# TC37XPD register map
Vendor: Infineon; Series: ATVMC; File version: 100
CPU: other r0p0, little endian, MPU, FPU, vendor SysTick, 4 interrupt priority bits
Registers are 32-bit, read-write, reset 0x0 unless marked. A register's access mark holds for its fields unless they carry their own. Offsets are from the block's base; [hi:lo] are bit positions; lines under a group give offsets from that group; {n}, {i} and the like mark numbered series; 'fields as' and 'values as' point back to an identical list.

## CPU0 (part 1 of 2) — CPU
Base 0xF8800000
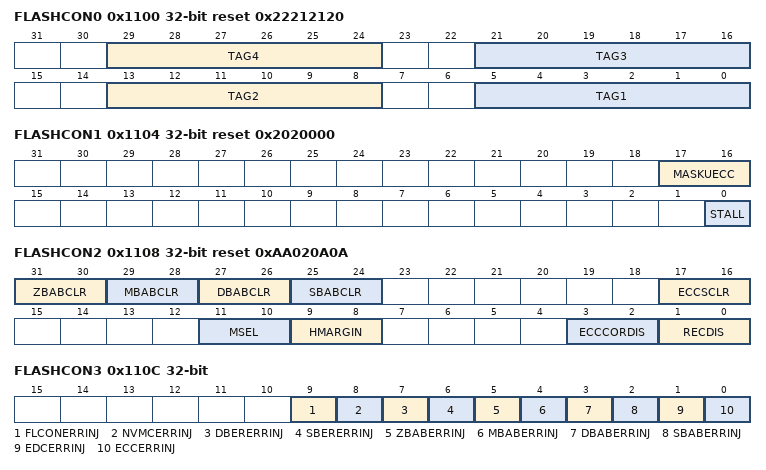
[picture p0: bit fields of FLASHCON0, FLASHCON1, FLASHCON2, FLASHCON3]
0x1100 FLASHCON0 reset 0x22212120 (reset mask 0xE2E1E1E0) — CPUx Flash Configuration Register 0 resetvalue={Application Reset:0x3F3F3F3F,CFS Value:0x22212120}
  [29:24] TAG4 — Flash Prefetch Buffer 4 Configuration. FPB is assigned to on chip bus master with master tag id equal to TAG4.
  [21:16] TAG3 — Flash Prefetch Buffer 3 Configuration. FPB is assigned to on chip bus master with master tag id equal to TAG3.
  [13:8] TAG2 — Flash Prefetch Buffer 2 Configuration. FPB is assigned to on xa0 chip xa0 bus master with master tag id equal to TAG2.
  [5:0] TAG1 — Flash Prefetch Buffer 1 Configuration. FPB is assigned to on xa0 chip xa0 bus master with master tag id equal to TAG1.
0x1104 FLASHCON1 reset 0x2020000 — CPUx Flash Configuration Register 1 resetvalue={Application Reset:0x2020000}
  [17:16] MASKUECC — Mask PFLASH Uncorrectable ECC Bit Error. No value other than 01 B or 10 B shall be programmed in the register bitfields. The system will behave as specified for 10 B if 00 B or 11 B is programmed.
  [0] STALL — Stall Bus Request. This field must not be changed while any bank is busy. The results are unpredictable. It is strongly recommended to configure this field once and avoid changing it during operation. Reading a flash bank erase counter or status register in Sleep Mode must result in a bus error independent of this field although it reports 8220 busy 8221 .
    0=Error0 (0 B Error Reading local PFlash bank erase counter or status registers when DMU STATUS.PxBUSY is set generates a bus error.); 1=1 B Stall Reading local PFlash bank erase counter or status registers when DMU HF STATUS.PxBUSY is set delays the response by inserting additional wait cycles until PxBUSY is cleared
0x1108 FLASHCON2 access per field reset 0xAA020A0A — CPUx Flash Configuration Register 2 resetvalue={Application Reset:0x0AA020A0A}
  [31:30] ZBABCLR wo — Clear ZBAB Record Registers ZBABCLR. The system will behave as specified for 10 B if 00 B or 11 B is programmed and an alarm will be generated.
  [29:28] MBABCLR wo — Clear MBAB Record Registers. The system will behave as specified for 10 B if 00 B or 11 B is programmed and an alarm will be generated.
  [27:26] DBABCLR wo — Clear DBAB Record Registers. The system will behave as specified for 10 B if 00 B or 11 B is programmed and an alarm will be generated.
  [25:24] SBABCLR wo — Clear SBAB Record Registers. The system will behave as specified for 10 B if 00 B or 11 B is programmed and an alarm will be generated.
  [17:16] ECCSCLR wo — Clear ECC Status Register. The system will behave as specified for 10 B if 00 B or 11 B is programmed and an alarm will be generated.
  [11:10] MSEL rw — Margin Read Selection. The system will behave as specified for 10 B if 00 B or 11 B is programmed and an alarm will be generated.
  [9:8] HMARGIN rw — Hard Margin Selection. This register setting is effective only if FLASHCON2.MSEL 01 B . The system will behave as specified for 10 B if 00 B or 11 B is programmed and an alarm will be generated.
  [3:2] ECCCORDIS rw — ECC Correction Disable ECCCORDIS. The system will behave as specified for 10 B if 00 B or 11 B is programmed and an alarm will be generated on the next read.
  [1:0] RECDIS rw — Address Buffer Recording Disable. The system will behave as specified for 10 B if 00 B or 11 B is programmed and an alarm will be generated. SBAB DBAB MBAB and ZBAB alarms will not be generated if RECDIS is 01 B .
0x110C FLASHCON3 — CPUx Flash Configuration Register 3 resetvalue={Application Reset:0x0}
  [9] FLCONERRINJ — Flashcon Error FLCONER Injection. Setting this bit enforces an error from the error detection logic covering FLASHCON complement pair register bits in the PFRWB RECDIS ECCCORDIS HMARGIN MSEL and all CLR bits and can be used to check the correct function of the FLCONER SMU alarm.
  [8] NVMCERRINJ — NVM Configuration NVMCER Injection. Setting this bit enforces an error from the error detection logic covering NVM configuration registers and can be used to check the correct function of the NVMCER SMU alarm.
  [7] DBERERRINJ — Double Bit Error DBER Injection. Setting this bit generates DBER SMU alarm and can be used to check the correct function of the DBER SMU alarm.
  [6] SBERERRINJ — Single Bit Error SBER Injection . Setting this bit generates SBER SMU alarm and can be used to check the correct function of this alarm.
  [5] ZBABERRINJ — Uncorrected All Zeros Bits Address Buffer ZBAB Error Injection. Error injection logic to check the correct function of the SMU alarm.
  [4] MBABERRINJ — Uncorrected Multi Bit Address Buffer MBAB Error Injection. Error injection logic to check the correct function of the SMU alarm.
  [3] DBABERRINJ — Corrected Double Bits Address Buffer DBAB Error Injection. Error injection logic to check the correct function of the SMU alarm.
  [2] SBABERRINJ — Corrected Single Bits Address Buffer SBAB Error Injection. Error injection logic to check the correct function of the SMU alarm.
  [1] EDCERRINJ — EDC Error Injection. Setting this bit enforces an error in the EDC checker logic. This can be used to check the correct function of this circuit.
  [0] ECCERRINJ — ECC Error Injection . Setting this bit enforces an error in the ECC error correction supervision circuit. This can be used to check the correct function of this circuit.
0x1110 FLASHCON4 — CPUx Flash Configuration Register 4 resetvalue={Application Reset:0x0}
  [0] DDIS — Disable direct LPB access. Disable direct access by the CPU to the Local Pflash Bank LPB .
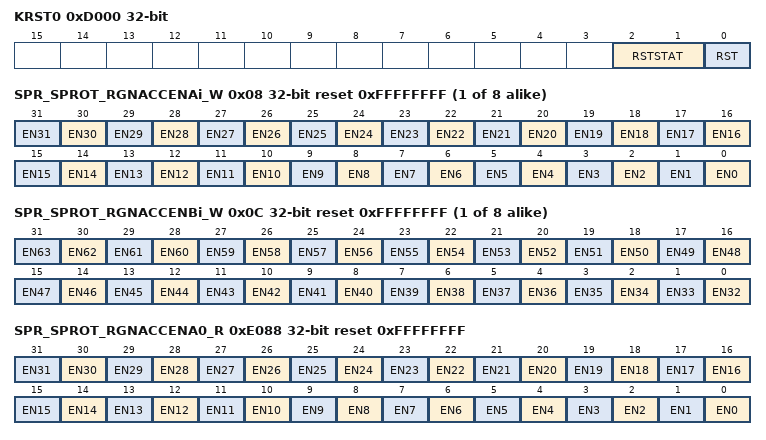
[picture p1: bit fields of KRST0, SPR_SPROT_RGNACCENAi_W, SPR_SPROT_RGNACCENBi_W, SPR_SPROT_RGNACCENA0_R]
0xD000 KRST0 access per field — CPUx Reset Register 0 resetvalue={Application Reset:0x0}
  [2:1] RSTSTAT ro — Kernel Reset Status RSTSTAT. This bit indicates wether a kernel reset was executed or not. This bit is set immediately after the execution of a kernel reset. These bits can be cleared by writing 180 1 180 to the CLR bit in the related KRSTCLR register.
  [0] RST rw — Kernel Reset RST. This reset bit can be used to request a kernel reset. The kernel reset will be executed if the reset bits of both kernel registers are set. The RST bit will be cleared re set to 180 0 180 by the BPI FPI after the kernel reset was executed.
0xD004 KRST1 — CPUx Reset Register 1 resetvalue={Application Reset:0x0}
  [0] RST — Kernel Reset RST. This reset bit can be used to request a kernel reset. The kernel reset will be executed if the reset bits of both kernel reset registers is set. The RST bit will be cleared re set to 180 0 180 after the kernel reset was executed.
0xD008 KRSTCLR wo — CPUx Reset Clear Register resetvalue={Application Reset:0x0}
  [0] CLR — Kernel Reset Status Clear CLR. Read always as 0.
{0xE000+0x10*i} RGN[{i}] (i=0..7) group
  0x00 SPR_SPROT_RGNLAi — CPUx Safety Protection SPR Region Lower Address Register 0 resetvalue={Application Reset:0x0}
    [31:5] ADDR — Region Lower Address ADDR. Bits 31 to 5 of the address which is the lower bound of the defined memory region
  0x04 SPR_SPROT_RGNUAi reset 0xFFFFFFE0 — CPUx Safety Protection SPR Region Upper Address Register 0 resetvalue={Application Reset:0x0FFFFFFE0}
    [31:5] ADDR — Region Upper Address ADDR. Bits 31 to 5 of the address which is the upper bound of the defined memory region
  0x08 SPR_SPROT_RGNACCENAi_W reset 0xFFFFFFFF — CPUx Safety Protection SPR Region Write Access Enable Register A0 resetvalue={Application Reset:0x0FFFFFFFF}
    [n] EN{n} (n=0..31) — Access Enable for Master TAG ID 31 EN31. This bit enables write access to the module kernel addresses for transactions with the Master TAG ID n
  0x0C SPR_SPROT_RGNACCENBi_W reset 0xFFFFFFFF — CPUx Safety Protection SPR Region Write Access Enable Register B0 resetvalue={Application Reset:0x0FFFFFFFF}
    [n-32] EN{n} (n=32..63) — Access Enable for Master TAG ID 63 EN63. This bit enables write access to the module kernel addresses for transactions with the Master TAG ID n
0xE088 SPR_SPROT_RGNACCENA0_R reset 0xFFFFFFFF — CPUx Safety Protection SPR Region Read Access Enable Register A7 resetvalue={Application Reset:0x0FFFFFFFF}
  [n] EN{n} (n=0..31) — Access Enable for Master TAG ID 31 EN31. This bit enables read access from the module kernel addresses for transactions with the Master TAG ID n
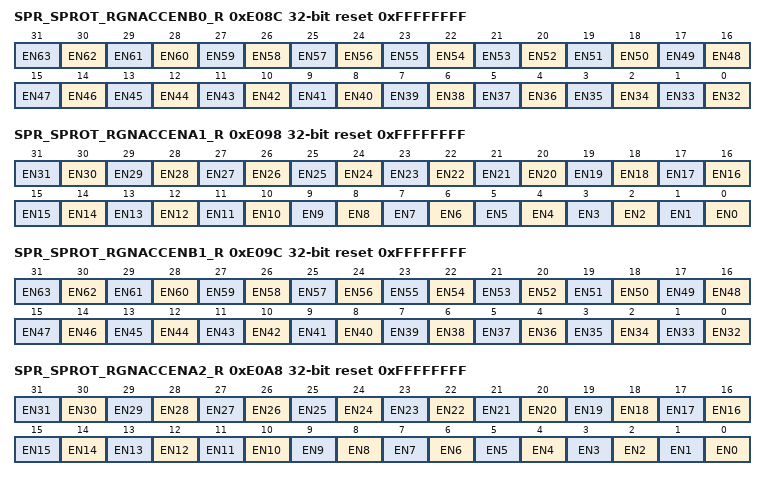
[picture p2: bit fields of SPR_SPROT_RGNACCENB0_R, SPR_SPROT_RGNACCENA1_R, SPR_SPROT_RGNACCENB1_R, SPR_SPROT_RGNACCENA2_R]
0xE08C SPR_SPROT_RGNACCENB0_R reset 0xFFFFFFFF — CPUx Safety Protection SPR Region Read Access Enable Register B7 resetvalue={Application Reset:0x0FFFFFFFF}
  [n-32] EN{n} (n=32..63) — Access Enable for Master TAG ID 63 EN63. This bit enables read access from the module kernel addresses for transactions with the Master TAG ID n
0xE098 SPR_SPROT_RGNACCENA1_R reset 0xFFFFFFFF — CPUx Safety Protection SPR Region Read Access Enable Register A7 resetvalue={Application Reset:0x0FFFFFFFF}
  fields as SPR_SPROT_RGNACCENA0_R
0xE09C SPR_SPROT_RGNACCENB1_R reset 0xFFFFFFFF — CPUx Safety Protection SPR Region Read Access Enable Register B7 resetvalue={Application Reset:0x0FFFFFFFF}
  fields as SPR_SPROT_RGNACCENB0_R
0xE0A8 SPR_SPROT_RGNACCENA2_R reset 0xFFFFFFFF — CPUx Safety Protection SPR Region Read Access Enable Register A7 resetvalue={Application Reset:0x0FFFFFFFF}
  fields as SPR_SPROT_RGNACCENA0_R
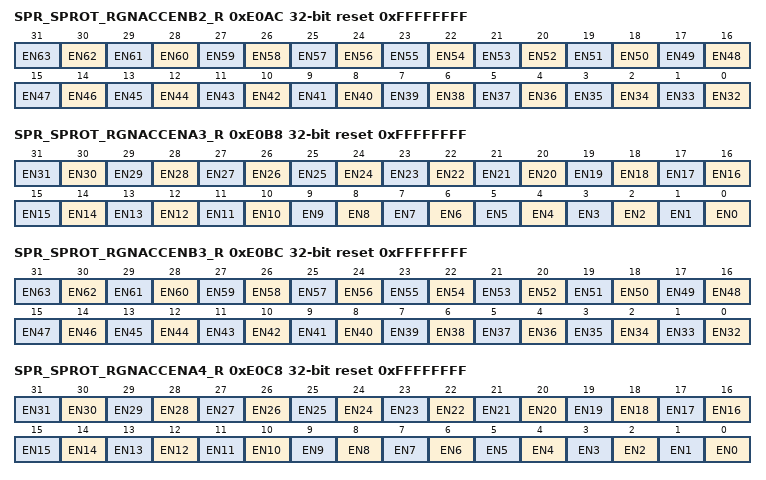
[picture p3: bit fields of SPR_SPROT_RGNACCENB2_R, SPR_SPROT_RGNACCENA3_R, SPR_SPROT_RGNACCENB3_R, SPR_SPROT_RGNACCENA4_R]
0xE0AC SPR_SPROT_RGNACCENB2_R reset 0xFFFFFFFF — CPUx Safety Protection SPR Region Read Access Enable Register B7 resetvalue={Application Reset:0x0FFFFFFFF}
  fields as SPR_SPROT_RGNACCENB0_R
0xE0B8 SPR_SPROT_RGNACCENA3_R reset 0xFFFFFFFF — CPUx Safety Protection SPR Region Read Access Enable Register A7 resetvalue={Application Reset:0x0FFFFFFFF}
  fields as SPR_SPROT_RGNACCENA0_R
0xE0BC SPR_SPROT_RGNACCENB3_R reset 0xFFFFFFFF — CPUx Safety Protection SPR Region Read Access Enable Register B7 resetvalue={Application Reset:0x0FFFFFFFF}
  fields as SPR_SPROT_RGNACCENB0_R
0xE0C8 SPR_SPROT_RGNACCENA4_R reset 0xFFFFFFFF — CPUx Safety Protection SPR Region Read Access Enable Register A7 resetvalue={Application Reset:0x0FFFFFFFF}
  fields as SPR_SPROT_RGNACCENA0_R
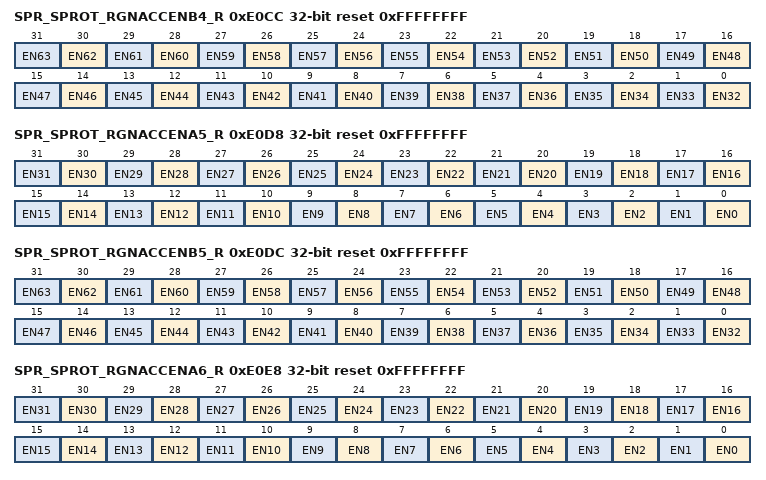
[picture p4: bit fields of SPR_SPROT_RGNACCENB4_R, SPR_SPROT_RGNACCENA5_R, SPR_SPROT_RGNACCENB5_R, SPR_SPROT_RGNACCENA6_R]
0xE0CC SPR_SPROT_RGNACCENB4_R reset 0xFFFFFFFF — CPUx Safety Protection SPR Region Read Access Enable Register B7 resetvalue={Application Reset:0x0FFFFFFFF}
  fields as SPR_SPROT_RGNACCENB0_R
0xE0D8 SPR_SPROT_RGNACCENA5_R reset 0xFFFFFFFF — CPUx Safety Protection SPR Region Read Access Enable Register A7 resetvalue={Application Reset:0x0FFFFFFFF}
  fields as SPR_SPROT_RGNACCENA0_R
0xE0DC SPR_SPROT_RGNACCENB5_R reset 0xFFFFFFFF — CPUx Safety Protection SPR Region Read Access Enable Register B7 resetvalue={Application Reset:0x0FFFFFFFF}
  fields as SPR_SPROT_RGNACCENB0_R
0xE0E8 SPR_SPROT_RGNACCENA6_R reset 0xFFFFFFFF — CPUx Safety Protection SPR Region Read Access Enable Register A7 resetvalue={Application Reset:0x0FFFFFFFF}
  fields as SPR_SPROT_RGNACCENA0_R
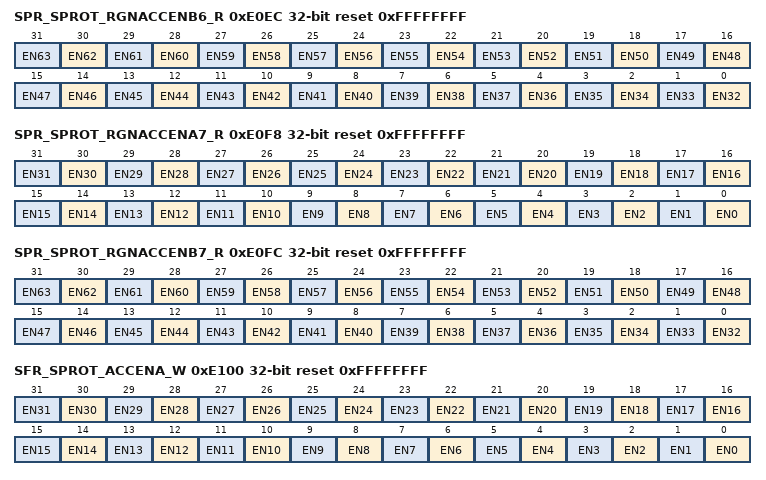
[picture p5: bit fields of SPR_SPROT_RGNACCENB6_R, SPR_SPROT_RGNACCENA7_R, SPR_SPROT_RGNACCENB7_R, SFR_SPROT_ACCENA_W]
0xE0EC SPR_SPROT_RGNACCENB6_R reset 0xFFFFFFFF — CPUx Safety Protection SPR Region Read Access Enable Register B7 resetvalue={Application Reset:0x0FFFFFFFF}
  fields as SPR_SPROT_RGNACCENB0_R
0xE0F8 SPR_SPROT_RGNACCENA7_R reset 0xFFFFFFFF — CPUx Safety Protection SPR Region Read Access Enable Register A7 resetvalue={Application Reset:0x0FFFFFFFF}
  fields as SPR_SPROT_RGNACCENA0_R
0xE0FC SPR_SPROT_RGNACCENB7_R reset 0xFFFFFFFF — CPUx Safety Protection SPR Region Read Access Enable Register B7 resetvalue={Application Reset:0x0FFFFFFFF}
  fields as SPR_SPROT_RGNACCENB0_R
0xE100 SFR_SPROT_ACCENA_W reset 0xFFFFFFFF — CPUx Safety Protection Register Access Enable Register A resetvalue={Application Reset:0x0FFFFFFFF}
  fields as RGN[0].SPR_SPROT_RGNACCENAi_W
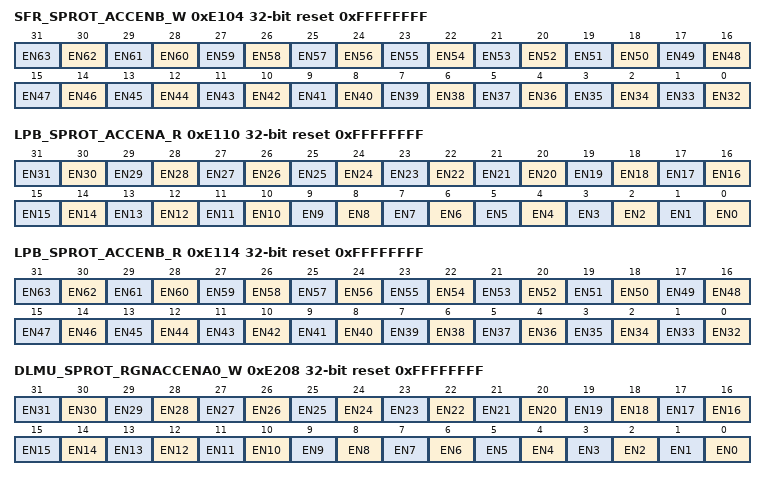
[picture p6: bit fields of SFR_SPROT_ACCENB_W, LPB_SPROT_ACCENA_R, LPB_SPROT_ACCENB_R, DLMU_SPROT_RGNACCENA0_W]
0xE104 SFR_SPROT_ACCENB_W reset 0xFFFFFFFF — CPUx Safety Protection Region Access Enable Register B resetvalue={Application Reset:0x0FFFFFFFF}
  fields as RGN[0].SPR_SPROT_RGNACCENBi_W
0xE110 LPB_SPROT_ACCENA_R reset 0xFFFFFFFF — CPUx Safety Protection Region LPB Read Access Enable Register A resetvalue={Application Reset:0x0FFFFFFFF}
  fields as SPR_SPROT_RGNACCENA0_R
0xE114 LPB_SPROT_ACCENB_R reset 0xFFFFFFFF — CPUx Safety Protection Region LPB Read Access Enable Register B resetvalue={Application Reset:0x0FFFFFFFF}
  fields as SPR_SPROT_RGNACCENB0_R
0xE200 DLMU_SPROT_RGNLA0 — CPUx Safety Protection DLMU Region Lower Address Register 7 resetvalue={Application Reset:0x0}
  fields as RGN[0].SPR_SPROT_RGNLAi
0xE204 DLMU_SPROT_RGNUA0 reset 0xFFFFFFE0 — CPUx Safety protection DLMU Region Upper Address Register 7 resetvalue={Application Reset:0x0FFFFFFE0}
  fields as RGN[0].SPR_SPROT_RGNUAi
0xE208 DLMU_SPROT_RGNACCENA0_W reset 0xFFFFFFFF — CPUx Safety Protection Region DLMU Write Access Enable Register A7 resetvalue={Application Reset:0x0FFFFFFFF}
  fields as RGN[0].SPR_SPROT_RGNACCENAi_W
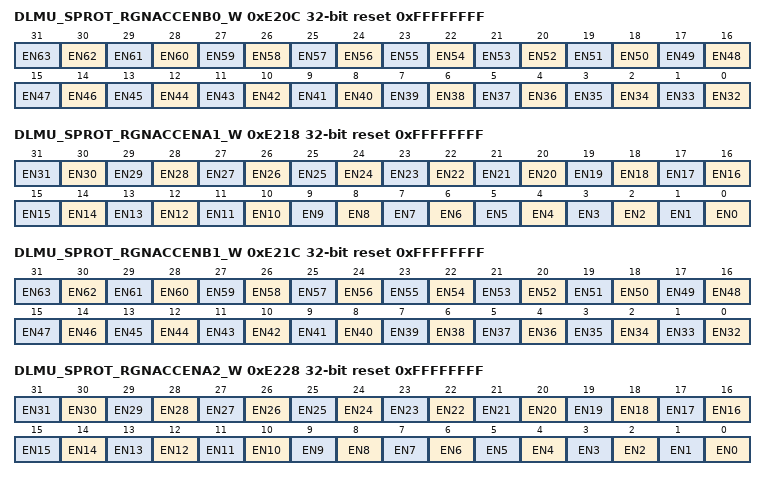
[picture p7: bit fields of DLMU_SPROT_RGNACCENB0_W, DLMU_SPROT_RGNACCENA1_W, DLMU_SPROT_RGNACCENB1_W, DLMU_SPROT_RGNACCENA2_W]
0xE20C DLMU_SPROT_RGNACCENB0_W reset 0xFFFFFFFF — CPUx Safety Protection Region DLMU Write Access Enable Register B7 resetvalue={Application Reset:0x0FFFFFFFF}
  fields as RGN[0].SPR_SPROT_RGNACCENBi_W
0xE210 DLMU_SPROT_RGNLA1 — CPUx Safety Protection DLMU Region Lower Address Register 7 resetvalue={Application Reset:0x0}
  fields as RGN[0].SPR_SPROT_RGNLAi
0xE214 DLMU_SPROT_RGNUA1 reset 0xFFFFFFE0 — CPUx Safety protection DLMU Region Upper Address Register 7 resetvalue={Application Reset:0x0FFFFFFE0}
  fields as RGN[0].SPR_SPROT_RGNUAi
0xE218 DLMU_SPROT_RGNACCENA1_W reset 0xFFFFFFFF — CPUx Safety Protection Region DLMU Write Access Enable Register A7 resetvalue={Application Reset:0x0FFFFFFFF}
  fields as RGN[0].SPR_SPROT_RGNACCENAi_W
0xE21C DLMU_SPROT_RGNACCENB1_W reset 0xFFFFFFFF — CPUx Safety Protection Region DLMU Write Access Enable Register B7 resetvalue={Application Reset:0x0FFFFFFFF}
  fields as RGN[0].SPR_SPROT_RGNACCENBi_W
0xE220 DLMU_SPROT_RGNLA2 — CPUx Safety Protection DLMU Region Lower Address Register 7 resetvalue={Application Reset:0x0}
  fields as RGN[0].SPR_SPROT_RGNLAi
0xE224 DLMU_SPROT_RGNUA2 reset 0xFFFFFFE0 — CPUx Safety protection DLMU Region Upper Address Register 7 resetvalue={Application Reset:0x0FFFFFFE0}
  fields as RGN[0].SPR_SPROT_RGNUAi
0xE228 DLMU_SPROT_RGNACCENA2_W reset 0xFFFFFFFF — CPUx Safety Protection Region DLMU Write Access Enable Register A7 resetvalue={Application Reset:0x0FFFFFFFF}
  fields as RGN[0].SPR_SPROT_RGNACCENAi_W
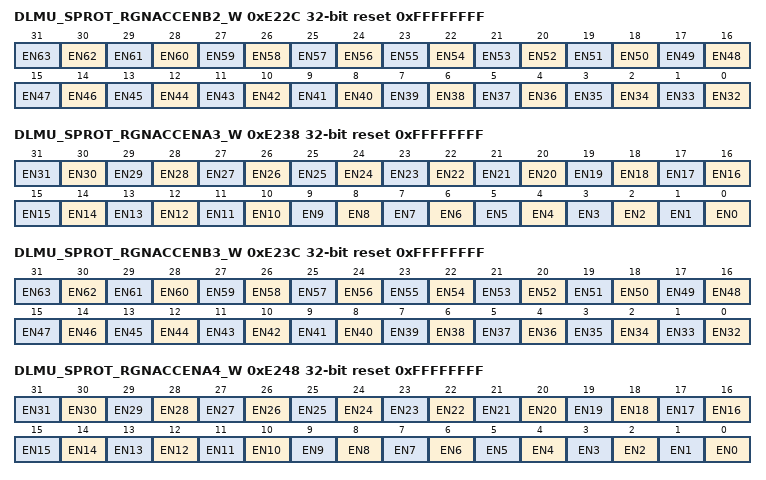
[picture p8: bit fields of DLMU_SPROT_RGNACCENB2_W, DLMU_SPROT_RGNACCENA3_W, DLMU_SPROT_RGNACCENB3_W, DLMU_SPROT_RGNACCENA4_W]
0xE22C DLMU_SPROT_RGNACCENB2_W reset 0xFFFFFFFF — CPUx Safety Protection Region DLMU Write Access Enable Register B7 resetvalue={Application Reset:0x0FFFFFFFF}
  fields as RGN[0].SPR_SPROT_RGNACCENBi_W
0xE230 DLMU_SPROT_RGNLA3 — CPUx Safety Protection DLMU Region Lower Address Register 7 resetvalue={Application Reset:0x0}
  fields as RGN[0].SPR_SPROT_RGNLAi
0xE234 DLMU_SPROT_RGNUA3 reset 0xFFFFFFE0 — CPUx Safety protection DLMU Region Upper Address Register 7 resetvalue={Application Reset:0x0FFFFFFE0}
  fields as RGN[0].SPR_SPROT_RGNUAi
0xE238 DLMU_SPROT_RGNACCENA3_W reset 0xFFFFFFFF — CPUx Safety Protection Region DLMU Write Access Enable Register A7 resetvalue={Application Reset:0x0FFFFFFFF}
  fields as RGN[0].SPR_SPROT_RGNACCENAi_W
0xE23C DLMU_SPROT_RGNACCENB3_W reset 0xFFFFFFFF — CPUx Safety Protection Region DLMU Write Access Enable Register B7 resetvalue={Application Reset:0x0FFFFFFFF}
  fields as RGN[0].SPR_SPROT_RGNACCENBi_W
0xE240 DLMU_SPROT_RGNLA4 — CPUx Safety Protection DLMU Region Lower Address Register 7 resetvalue={Application Reset:0x0}
  fields as RGN[0].SPR_SPROT_RGNLAi
0xE244 DLMU_SPROT_RGNUA4 reset 0xFFFFFFE0 — CPUx Safety protection DLMU Region Upper Address Register 7 resetvalue={Application Reset:0x0FFFFFFE0}
  fields as RGN[0].SPR_SPROT_RGNUAi
0xE248 DLMU_SPROT_RGNACCENA4_W reset 0xFFFFFFFF — CPUx Safety Protection Region DLMU Write Access Enable Register A7 resetvalue={Application Reset:0x0FFFFFFFF}
  fields as RGN[0].SPR_SPROT_RGNACCENAi_W
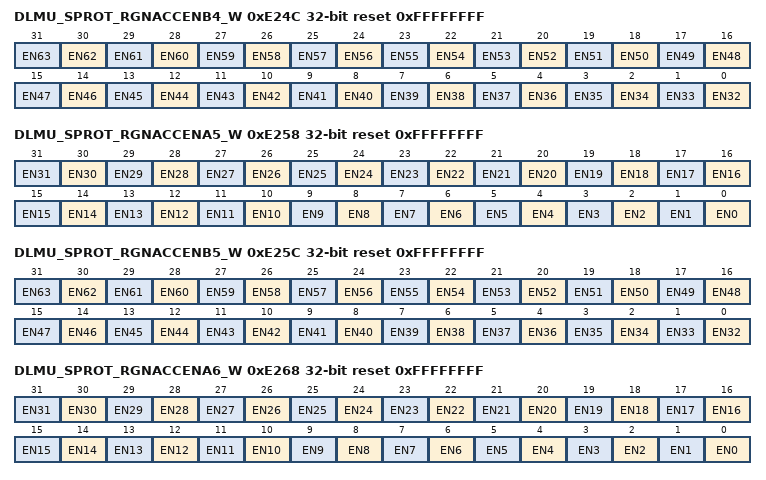
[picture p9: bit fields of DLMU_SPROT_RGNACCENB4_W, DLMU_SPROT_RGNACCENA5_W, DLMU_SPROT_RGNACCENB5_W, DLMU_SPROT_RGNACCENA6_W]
0xE24C DLMU_SPROT_RGNACCENB4_W reset 0xFFFFFFFF — CPUx Safety Protection Region DLMU Write Access Enable Register B7 resetvalue={Application Reset:0x0FFFFFFFF}
  fields as RGN[0].SPR_SPROT_RGNACCENBi_W
0xE250 DLMU_SPROT_RGNLA5 — CPUx Safety Protection DLMU Region Lower Address Register 7 resetvalue={Application Reset:0x0}
  fields as RGN[0].SPR_SPROT_RGNLAi
0xE254 DLMU_SPROT_RGNUA5 reset 0xFFFFFFE0 — CPUx Safety protection DLMU Region Upper Address Register 7 resetvalue={Application Reset:0x0FFFFFFE0}
  fields as RGN[0].SPR_SPROT_RGNUAi
0xE258 DLMU_SPROT_RGNACCENA5_W reset 0xFFFFFFFF — CPUx Safety Protection Region DLMU Write Access Enable Register A7 resetvalue={Application Reset:0x0FFFFFFFF}
  fields as RGN[0].SPR_SPROT_RGNACCENAi_W
0xE25C DLMU_SPROT_RGNACCENB5_W reset 0xFFFFFFFF — CPUx Safety Protection Region DLMU Write Access Enable Register B7 resetvalue={Application Reset:0x0FFFFFFFF}
  fields as RGN[0].SPR_SPROT_RGNACCENBi_W
0xE260 DLMU_SPROT_RGNLA6 — CPUx Safety Protection DLMU Region Lower Address Register 7 resetvalue={Application Reset:0x0}
  fields as RGN[0].SPR_SPROT_RGNLAi
0xE264 DLMU_SPROT_RGNUA6 reset 0xFFFFFFE0 — CPUx Safety protection DLMU Region Upper Address Register 7 resetvalue={Application Reset:0x0FFFFFFE0}
  fields as RGN[0].SPR_SPROT_RGNUAi
0xE268 DLMU_SPROT_RGNACCENA6_W reset 0xFFFFFFFF — CPUx Safety Protection Region DLMU Write Access Enable Register A7 resetvalue={Application Reset:0x0FFFFFFFF}
  fields as RGN[0].SPR_SPROT_RGNACCENAi_W
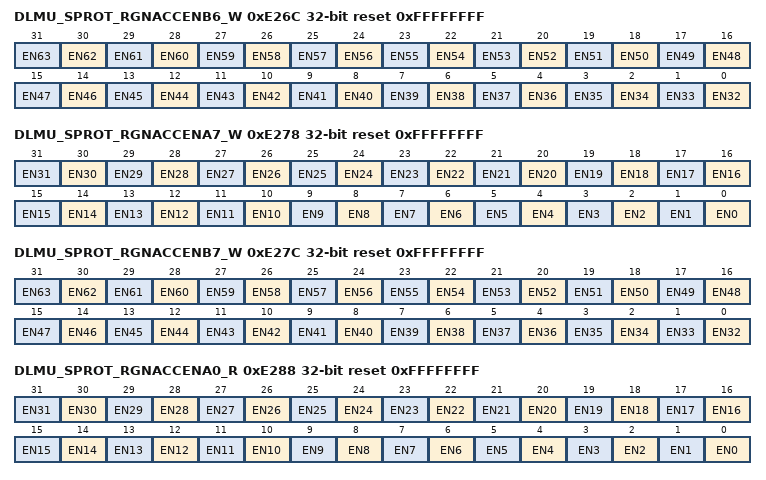
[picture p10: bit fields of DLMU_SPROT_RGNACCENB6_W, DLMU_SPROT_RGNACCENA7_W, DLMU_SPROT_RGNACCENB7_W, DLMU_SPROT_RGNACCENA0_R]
0xE26C DLMU_SPROT_RGNACCENB6_W reset 0xFFFFFFFF — CPUx Safety Protection Region DLMU Write Access Enable Register B7 resetvalue={Application Reset:0x0FFFFFFFF}
  fields as RGN[0].SPR_SPROT_RGNACCENBi_W
0xE270 DLMU_SPROT_RGNLA7 — CPUx Safety Protection DLMU Region Lower Address Register 7 resetvalue={Application Reset:0x0}
  fields as RGN[0].SPR_SPROT_RGNLAi
0xE274 DLMU_SPROT_RGNUA7 reset 0xFFFFFFE0 — CPUx Safety protection DLMU Region Upper Address Register 7 resetvalue={Application Reset:0x0FFFFFFE0}
  fields as RGN[0].SPR_SPROT_RGNUAi
0xE278 DLMU_SPROT_RGNACCENA7_W reset 0xFFFFFFFF — CPUx Safety Protection Region DLMU Write Access Enable Register A7 resetvalue={Application Reset:0x0FFFFFFFF}
  fields as RGN[0].SPR_SPROT_RGNACCENAi_W
0xE27C DLMU_SPROT_RGNACCENB7_W reset 0xFFFFFFFF — CPUx Safety Protection Region DLMU Write Access Enable Register B7 resetvalue={Application Reset:0x0FFFFFFFF}
  fields as RGN[0].SPR_SPROT_RGNACCENBi_W
0xE288 DLMU_SPROT_RGNACCENA0_R reset 0xFFFFFFFF — CPUx Safety Protection Region DLMU Read Access Enable Register A7 resetvalue={Application Reset:0x0FFFFFFFF}
  fields as SPR_SPROT_RGNACCENA0_R
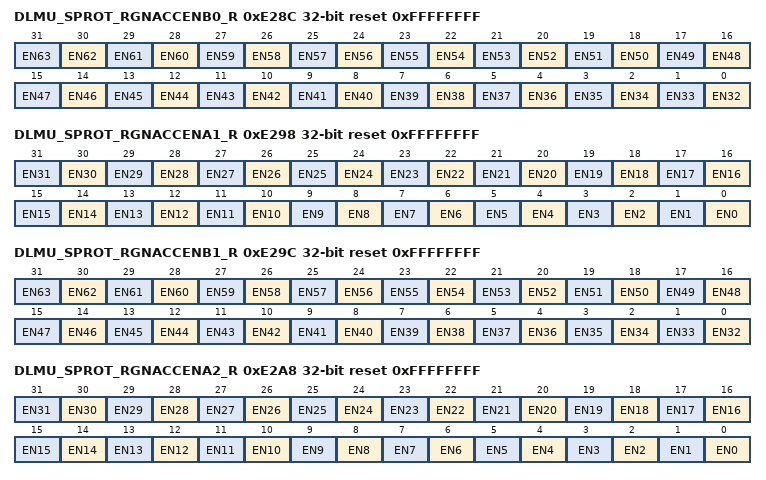
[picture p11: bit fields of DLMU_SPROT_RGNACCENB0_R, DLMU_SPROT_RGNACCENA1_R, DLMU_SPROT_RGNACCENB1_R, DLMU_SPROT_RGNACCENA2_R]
0xE28C DLMU_SPROT_RGNACCENB0_R reset 0xFFFFFFFF — CPUx Safety Protection Region DLMU Read Access Enable Register B7 resetvalue={Application Reset:0x0FFFFFFFF}
  fields as SPR_SPROT_RGNACCENB0_R
0xE298 DLMU_SPROT_RGNACCENA1_R reset 0xFFFFFFFF — CPUx Safety Protection Region DLMU Read Access Enable Register A7 resetvalue={Application Reset:0x0FFFFFFFF}
  fields as SPR_SPROT_RGNACCENA0_R
0xE29C DLMU_SPROT_RGNACCENB1_R reset 0xFFFFFFFF — CPUx Safety Protection Region DLMU Read Access Enable Register B7 resetvalue={Application Reset:0x0FFFFFFFF}
  fields as SPR_SPROT_RGNACCENB0_R
0xE2A8 DLMU_SPROT_RGNACCENA2_R reset 0xFFFFFFFF — CPUx Safety Protection Region DLMU Read Access Enable Register A7 resetvalue={Application Reset:0x0FFFFFFFF}
  fields as SPR_SPROT_RGNACCENA0_R
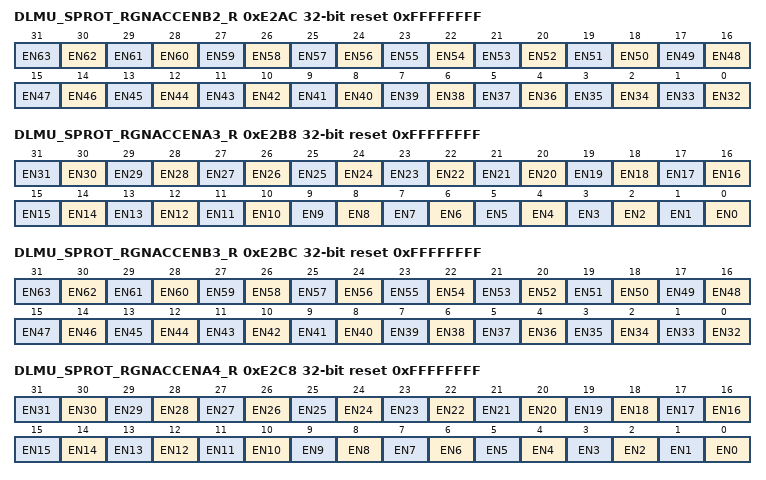
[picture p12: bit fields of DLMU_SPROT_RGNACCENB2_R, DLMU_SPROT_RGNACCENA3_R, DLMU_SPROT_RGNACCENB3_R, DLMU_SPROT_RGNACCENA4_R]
0xE2AC DLMU_SPROT_RGNACCENB2_R reset 0xFFFFFFFF — CPUx Safety Protection Region DLMU Read Access Enable Register B7 resetvalue={Application Reset:0x0FFFFFFFF}
  fields as SPR_SPROT_RGNACCENB0_R
0xE2B8 DLMU_SPROT_RGNACCENA3_R reset 0xFFFFFFFF — CPUx Safety Protection Region DLMU Read Access Enable Register A7 resetvalue={Application Reset:0x0FFFFFFFF}
  fields as SPR_SPROT_RGNACCENA0_R
0xE2BC DLMU_SPROT_RGNACCENB3_R reset 0xFFFFFFFF — CPUx Safety Protection Region DLMU Read Access Enable Register B7 resetvalue={Application Reset:0x0FFFFFFFF}
  fields as SPR_SPROT_RGNACCENB0_R
0xE2C8 DLMU_SPROT_RGNACCENA4_R reset 0xFFFFFFFF — CPUx Safety Protection Region DLMU Read Access Enable Register A7 resetvalue={Application Reset:0x0FFFFFFFF}
  fields as SPR_SPROT_RGNACCENA0_R
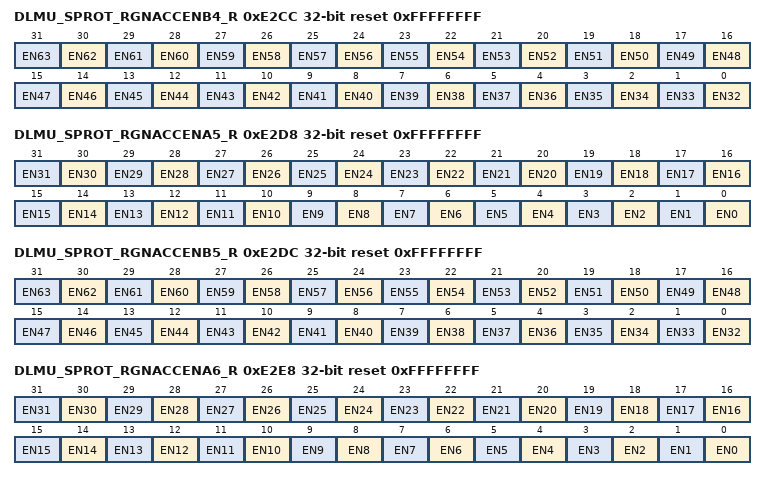
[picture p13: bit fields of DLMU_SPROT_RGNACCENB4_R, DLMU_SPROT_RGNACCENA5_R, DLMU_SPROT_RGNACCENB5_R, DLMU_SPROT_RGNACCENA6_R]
0xE2CC DLMU_SPROT_RGNACCENB4_R reset 0xFFFFFFFF — CPUx Safety Protection Region DLMU Read Access Enable Register B7 resetvalue={Application Reset:0x0FFFFFFFF}
  fields as SPR_SPROT_RGNACCENB0_R
0xE2D8 DLMU_SPROT_RGNACCENA5_R reset 0xFFFFFFFF — CPUx Safety Protection Region DLMU Read Access Enable Register A7 resetvalue={Application Reset:0x0FFFFFFFF}
  fields as SPR_SPROT_RGNACCENA0_R
0xE2DC DLMU_SPROT_RGNACCENB5_R reset 0xFFFFFFFF — CPUx Safety Protection Region DLMU Read Access Enable Register B7 resetvalue={Application Reset:0x0FFFFFFFF}
  fields as SPR_SPROT_RGNACCENB0_R
0xE2E8 DLMU_SPROT_RGNACCENA6_R reset 0xFFFFFFFF — CPUx Safety Protection Region DLMU Read Access Enable Register A7 resetvalue={Application Reset:0x0FFFFFFFF}
  fields as SPR_SPROT_RGNACCENA0_R
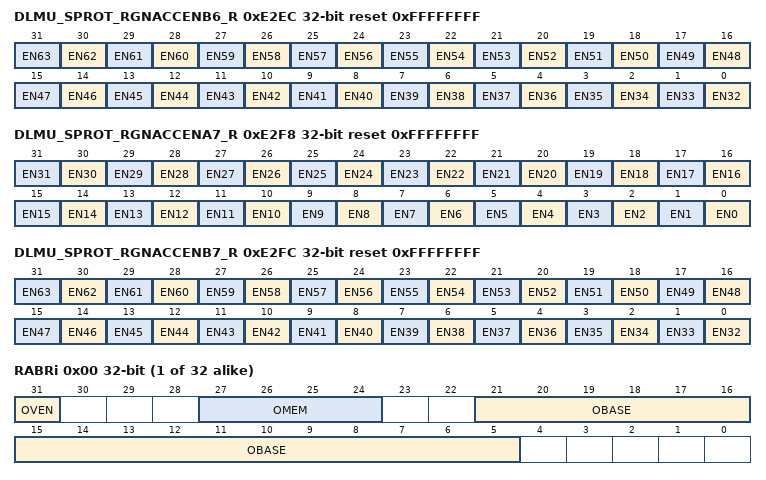
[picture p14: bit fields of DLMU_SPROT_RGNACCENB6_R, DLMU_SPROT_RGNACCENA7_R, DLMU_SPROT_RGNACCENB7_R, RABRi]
0xE2EC DLMU_SPROT_RGNACCENB6_R reset 0xFFFFFFFF — CPUx Safety Protection Region DLMU Read Access Enable Register B7 resetvalue={Application Reset:0x0FFFFFFFF}
  fields as SPR_SPROT_RGNACCENB0_R
0xE2F8 DLMU_SPROT_RGNACCENA7_R reset 0xFFFFFFFF — CPUx Safety Protection Region DLMU Read Access Enable Register A7 resetvalue={Application Reset:0x0FFFFFFFF}
  fields as SPR_SPROT_RGNACCENA0_R
0xE2FC DLMU_SPROT_RGNACCENB7_R reset 0xFFFFFFFF — CPUx Safety Protection Region DLMU Read Access Enable Register B7 resetvalue={Application Reset:0x0FFFFFFFF}
  fields as SPR_SPROT_RGNACCENB0_R
0xFB00 OSEL — CPUx Overlay Range Select Register resetvalue={Application Reset:0x0}
  [31:0] SHOVEN_x — Shadow Overlay Enable SHOVEN x . One enable bit is provided for each of the 32 overlay blocks.
{0xFB10+0xC*i} BLK[{i}] (i=0..31) group
  0x00 RABRi — CPUx Redirected Address Base Register 0 resetvalue={Application Reset:0x0}
    [31] OVEN — Overlay Enabled OVEN. This bit controls whether the overlay function of overlay block x is enabled. This bit can also be changed when OVCCON.OVSTP or OVCCON.OVSTRT is set. See OVCCON register description.
    [27:24] OMEM — Overlay Memory Select OMEM. Selects overlay memory used for redirection.
    [21:5] OBASE — Overlay Block Base Address OBASE. Bits 21..5 of the base address the overlay memory block in the overlay memory. If the corresponding bit in OMASK register is set to one OBASE bit value is used in the redirection address. If the corresponding bit in OMASK register is set to zero OBASE bit value is ignored.
  0x04 OTARi — CPUx Overlay Target Address Register 0 resetvalue={Application Reset:0x0}
    [27:5] TBASE — Target Base TBASE. This field holds the base address of the overlay memory block in the target memory. If the corresponding bit in OMASK register is set to one TBASE bit value is used in the address match. If the corresponding bit in OMASK register is set to zero TBASE bit value is ignored.
  0x08 OMASKi access per field reset 0xFFFFFE0 — CPUx Overlay Mask Register 0 resetvalue={Application Reset:0x0FFFFFE0}
    [27:17] ONE ro — Fixed 1 Values ONE. Corresponding address bits are participating in the address comparison. Corresponding final address bits are taken from RABRx.
    [16:5] OMASK rw — Overlay Address Mask OMASK. This bitfield determines the overlay block size and the bits used for address comparison and translation. ... Zero bits determine the corresponding address bits which are not used in the address comparison and thus determine the block size corresponding final address bits are derived from the original data address. One bits determine the corresponding address bits which are used for the address comparison corresponding final address bits are derived from RABRx register in case of address match.
0x11030 SEGEN — CPUx SRI Error Generation Register resetvalue={Application Reset:0x0}
  [31] AE — Activate Error Enable AE. Enabled the selective inverting of SRI ECC packet bits defined by ADFLIP. This bit will be cleared by hardware after the next SRI read or write transaction from the DMI.
  [9:8] ADTYPE — Type of error ADTYPE
  [7:0] ADFLIP — Address ECC Bit Flip ADFLIP. SRI address ECC Bits to be flipped on the next read or write transaction from the DMI when enabled by AE.
0x18004 TASK_ASI reset 0x1F — CPUx Task Address Space Identifier Register resetvalue={Application Reset:0x1F}
  [4:0] ASI — Address Space Identifier ASI. The ASI register contains the Address Space Identifier of the current process.
0x18100 PMA0 reset 0x300 — CPUx Data Access CacheabilityRegister resetvalue={Application Reset:0x300}
  [15:0] DAC — Data Access Cacheability Segments FHto 0H DAC. Note segments F H E H D H and A H are constrained to be non cacheable
0x18104 PMA1 reset 0x300 — CPUx Code Access CacheabilityRegister resetvalue={Application Reset:0x300}
  [15:0] CAC — Code Access Cacheability Segments FH 0H CAC. Note Segments F H E H C H A H are constrained to be non cacheable
0x18108 PMA2 ro reset 0xC000 — CPUx Peripheral Space Identifier register resetvalue={Application Reset:0x0C000}
  [15:0] PSI — Peripheral Space Identifier Segments FH 0H PSI
0x19000 DCON2 ro reset not defined — CPUx Data Control Register 2 resetvalue={Application Reset:0x0}
  [31:16] DSCRATCH_SZE — Data Scratch Size DSCRATCH SZE. In KBytes
  [15:0] DCACHE_SZE — Data Cache Size DCACHE SZE. In KBytes
0x1900C SMACON — CPUx SIST Mode Access Control Register resetvalue={Application Reset:0x0}
  [24] IODT — In Order Data Transactions IODT
0x19010 DSTR — CPUx Data Synchronous Trap Register resetvalue={Application Reset:0x0}
  [24] ALN — Alignment Error ALN. Data access causing alignment error.
  [20] CLE — Context Location Error CLE. Context operation to invalid location.
  [19] MPE — Memory Protection Error MPE. Data access violating memory protection.
  [18] CAC — CSFR Access Error CAC. Load or store to local CSFR space.
  [17] SCE — Segment Crossing Error SCE. Load or store access across segment boundary.
  [16] SDE — Segment Difference Error SDE. Load or store access where base address is in different segment to access address.
  [15] LOE — Load Overlay Error LOE. Load to invalid overlay address.
  [14] DTME — DTAG MSIST Error DTME. Access to memory mapped DTAG range outside of physically implemented memory.
  [6] CRE — Cache Refill Error CRE. A Cache Refill Error will be set whenever the SRI flags an error due a cache refill from external memory.
  [3] DRE — Local DLMU Range Error DRE. A DLMU Range Error occurs whenever an access to the local DLMU region is outside the physically implemented memory.
  [2] LBE — Load Bus Error LBE. A Load Bus Error will be set whenever the SRI flags an error due a load from external memory.
  [1] GAE — Global Address Error GAE. Load or store to local code scratch address outside of the lower 1MByte.
  [0] SRE — Scratch Range Error SRE. A scratch Range Error occurs whenever an access to the data scratch is outside the range of the SRAM.
0x19018 DATR — CPUx Data Asynchronous Trap Register resetvalue={Application Reset:0x0}
  [14] SOE — Store Overlay Error SOE
  [10] CFE — Cache Flush Error CFE
  [9] CWE — Cache Writeback Error CWE
  [3] SBE — Store Bus Error SBE
0x1901C DEADD ro — CPUx Data Error Address Register resetvalue={Application Reset:0x0}
  [31:0] ERROR_ADDRESS — Error Address ERROR ADDRESS
0x19020 DIEAR ro — CPUx Data Integrity Error Address Register resetvalue={Application Reset:0x0}
  [31:0] TA — Transaction Address TA. Physical address being accessed by operation that encountered data integrity error.
0x19024 DIETR access per field — CPUx Data Integrity Error Trap Register resetvalue={Application Reset:0x0}
  [16] IE_MTMV ro — Memory Test Mode Violation detected IE MTMV
  [15] IE_LPB ro — Integrity Error Local Pflash Bank IE LPB
  [14] IE_DLMU ro — Integrity Error DLMU IE DLMU
  [13] IE_BS ro — Bus Slave Access Indicator IE BS
  [12] IE_SP ro — Safety Protection Error Detected IE SP
  [11] IE_UNC ro — Dual Bit Error Detected IE UNC
  [10:5] E_INFO ro — Error Information E INFO. If IE BS 1 Bus Master Tag ID of requesting masterIf IE C 1 Cache way.
  [4] IE_BI ro — Integrity Error Bus Interface IE BI
  [3] IE_S ro — Integrity Error Scratchpad Memory IE S
  [2] IE_C ro — Integrity Error Cache Memory IE C
  [1] IE_T ro — Integrity Error Tag Memory IE T
  [0] IED rw — Integrity Error Detected IED
0x19040 DCON0 reset 0x2 — CPUx Data Memory Control Register resetvalue={Application Reset:0x2}
  [1] DCBYP — Data Cache Bypass DCBYP

## CPU1 (part 1 of 2) — CPU
Base 0xF8820000
Registers as CPU0; these are added or differ:
0x1100 FLASHCON0 reset 0x22202021 (reset mask 0xE2E0E0E1) — CPUx Flash Configuration Register 0 resetvalue={Application Reset:0x3F3F3F3F,CFS Value:0x22202021}
  fields as CPU0.FLASHCON0

## CPU2 (part 1 of 2) — CPU
Base 0xF8840000
Registers as CPU0; these are added or differ:
0x1100 FLASHCON0 (reset mask 0xC0C0C0C0) — CPUx Flash Configuration Register 0 resetvalue={Application Reset:0x3F3F3F3F,CFS Value:0x0}
  fields as CPU0.FLASHCON0
